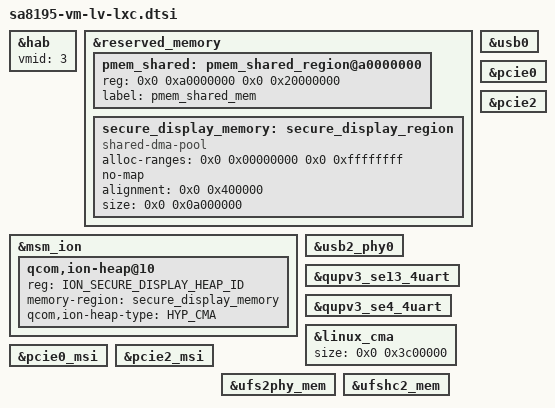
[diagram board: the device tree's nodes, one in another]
&hab {
	vmid = <3>;
};

&reserved_memory {
	pmem_shared: pmem_shared_region@a0000000 {
		reg = <0x0 0xa0000000 0x0 0x20000000>;
		label = "pmem_shared_mem";
	};

	secure_display_memory: secure_display_region {
		compatible = "shared-dma-pool";
		alloc-ranges = <0x0 0x00000000 0x0 0xffffffff>;
		no-map;
		alignment = <0x0 0x400000>;
		size = <0x0 0x0a000000>;
	};
};

#include "display/quin-vm-display-lxc.dtsi"

&msm_ion {
	qcom,ion-heap@10 {
		reg = <ION_SECURE_DISPLAY_HEAP_ID>;
		memory-region = <&secure_display_memory>;
		qcom,ion-heap-type = "HYP_CMA";
	};
};

&usb0 {
	status = "ok";
};

&usb2_phy0 {
	status = "ok";
};

&qupv3_se13_4uart {
	status = "ok";
};

&qupv3_se4_4uart {
	status = "ok";
};

&linux_cma {
	size = <0x0 0x3c00000>;
};

&pcie0_msi {
	status = "ok";
};

&pcie0 {
	status = "ok";
};

&pcie2_msi {
	status = "ok";
};

&pcie2 {
	status = "ok";
};

#include "sa8195-vm-lv-cnss-lxc.dtsi"
#include "sa8195-vm-ufs.dtsi"

&ufs2phy_mem {
	status = "ok";
};

&ufshc2_mem {
	status = "ok";
};
